# STM32H743 register map
File version: 2.4
CPU: CM7 r0p1, little endian, MPU, FPU, 4 interrupt priority bits
Registers are 32-bit, read-write, reset 0x0 unless marked. A register's access mark holds for its fields unless they carry their own. Offsets are from the block's base; [hi:lo] are bit positions; {n}, {i} and the like mark numbered series.

## LPUART1
Base 0x58000C00
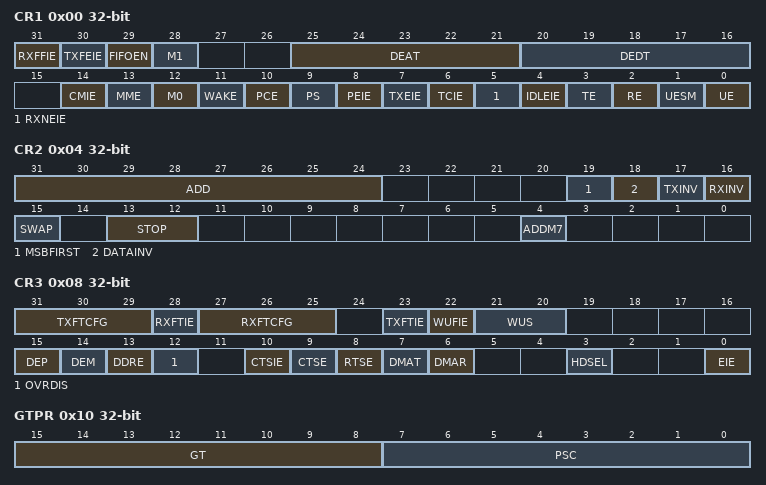
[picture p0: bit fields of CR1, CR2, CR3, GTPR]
0x00 CR1 — Control register 1
  [31] RXFFIE — RXFIFO Full interrupt enable
  [30] TXFEIE — TXFIFO empty interrupt enable
  [29] FIFOEN — FIFO mode enable
  [28] M1 — Word length
  [25:21] DEAT — Driver Enable assertion time
  [20:16] DEDT — Driver Enable deassertion time
  [14] CMIE — Character match interrupt enable
  [13] MME — Mute mode enable
  [12] M0 — Word length
  [11] WAKE — Receiver wakeup method
  [10] PCE — Parity control enable
  [9] PS — Parity selection
  [8] PEIE — PE interrupt enable
  [7] TXEIE — interrupt enable
  [6] TCIE — Transmission complete interrupt enable
  [5] RXNEIE — RXNE interrupt enable
  [4] IDLEIE — IDLE interrupt enable
  [3] TE — Transmitter enable
  [2] RE — Receiver enable
  [1] UESM — USART enable in Stop mode
  [0] UE — USART enable
0x04 CR2 — Control register 2
  [31:24] ADD — Address of the USART node
  [19] MSBFIRST — Most significant bit first
  [18] DATAINV — Binary data inversion
  [17] TXINV — TX pin active level inversion
  [16] RXINV — RX pin active level inversion
  [15] SWAP — Swap TX/RX pins
  [13:12] STOP — STOP bits
  [4] ADDM7 — 7-bit Address Detection/4-bit Address Detection
0x08 CR3 — Control register 3
  [31:29] TXFTCFG — TXFIFO threshold configuration
  [28] RXFTIE — RXFIFO threshold interrupt enable
  [27:25] RXFTCFG — Receive FIFO threshold configuration
  [23] TXFTIE — TXFIFO threshold interrupt enable
  [22] WUFIE — Wakeup from Stop mode interrupt enable
  [21:20] WUS — Wakeup from Stop mode interrupt flag selection
  [15] DEP — Driver enable polarity selection
  [14] DEM — Driver enable mode
  [13] DDRE — DMA Disable on Reception Error
  [12] OVRDIS — Overrun Disable
  [10] CTSIE — CTS interrupt enable
  [9] CTSE — CTS enable
  [8] RTSE — RTS enable
  [7] DMAT — DMA enable transmitter
  [6] DMAR — DMA enable receiver
  [3] HDSEL — Half-duplex selection
  [0] EIE — Error interrupt enable
0x0C BRR — Baud rate register
  [19:0] BRR
0x10 GTPR — Guard time and prescaler register
  [15:8] GT — Guard time value
  [7:0] PSC — Prescaler value
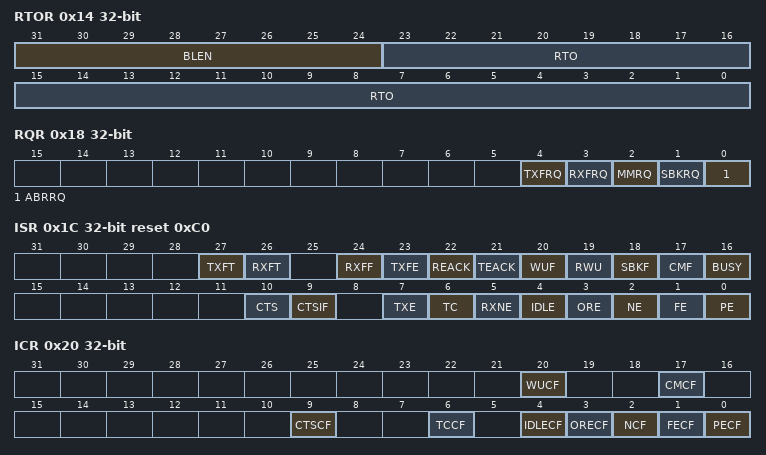
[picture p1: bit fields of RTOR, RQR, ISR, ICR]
0x14 RTOR — Receiver timeout register
  [31:24] BLEN — Block Length
  [23:0] RTO — Receiver timeout value
0x18 RQR wo — Request register
  [4] TXFRQ — Transmit data flush request
  [3] RXFRQ — Receive data flush request
  [2] MMRQ — Mute mode request
  [1] SBKRQ — Send break request
  [0] ABRRQ — Auto baud rate request
0x1C ISR ro reset 0xC0 — Interrupt & status register
  [27] TXFT — TXFIFO threshold flag
  [26] RXFT — RXFIFO threshold flag
  [24] RXFF — RXFIFO Full
  [23] TXFE — TXFIFO Empty
  [22] REACK
  [21] TEACK
  [20] WUF
  [19] RWU
  [18] SBKF
  [17] CMF
  [16] BUSY
  [10] CTS
  [9] CTSIF
  [7] TXE
  [6] TC
  [5] RXNE
  [4] IDLE
  [3] ORE
  [2] NE
  [1] FE
  [0] PE
0x20 ICR wo — Interrupt flag clear register
  [20] WUCF — Wakeup from Stop mode clear flag
  [17] CMCF — Character match clear flag
  [9] CTSCF — CTS clear flag
  [6] TCCF — Transmission complete clear flag
  [4] IDLECF — Idle line detected clear flag
  [3] ORECF — Overrun error clear flag
  [2] NCF — Noise detected clear flag
  [1] FECF — Framing error clear flag
  [0] PECF — Parity error clear flag
0x24 RDR ro — Receive data register
  [8:0] RDR — Receive data value
0x28 TDR — Transmit data register
  [8:0] TDR — Transmit data value
0x2C PRESC — Prescaler register
  [3:0] PRESCALER — Clock prescaler

## RAMECC1 — ECC controller is associated to each RAM area
Base 0x52009000
Same registers: RAMECC2 0x48023000
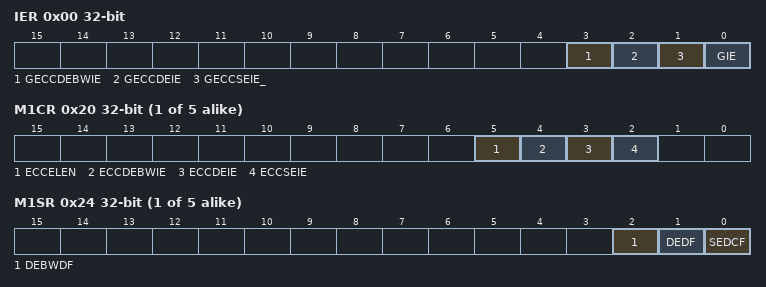
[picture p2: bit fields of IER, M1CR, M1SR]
0x00 IER — RAMECC interrupt enable register
  [3] GECCDEBWIE — Global ECC double error on byte write (BW) interrupt enable
  [2] GECCDEIE — Global ECC double error interrupt enable
  [1] GECCSEIE_ — Global ECC single error interrupt enable
  [0] GIE — Global interrupt enable
{0x0+0x20*i} M{i}CR (i=1..5) — RAMECC monitor x configuration register
  [5] ECCELEN — ECC error latching enable
  [4] ECCDEBWIE — ECC double error on byte write (BW) interrupt enable
  [3] ECCDEIE — ECC double error interrupt enable
  [2] ECCSEIE — ECC single error interrupt enable
{0x4+0x20*i} M{i}SR (i=1..5) — RAMECC monitor x status register
  [2] DEBWDF — ECC double error on byte write (BW) detected flag
  [1] DEDF — ECC double error detected flag
  [0] SEDCF — ECC single error detected and corrected flag
{0x8+0x20*i} M{i}FAR ro (i=1..4) — RAMECC monitor x failing address register
  [31:0] FADD — ECC error failing address
{0xC+0x20*i} M{i}FDRL ro (i=1..5) — RAMECC monitor x failing data low register
  [31:0] FDATAL — Failing data low
0x30 M1FDRH ro — RAMECC monitor x failing data high register
  [31:0] FDATAH — Failing data high (64-bit memory)
0x34 M1FECR — RAMECC monitor x failing ECC error code register
  [31:0] FEC — Failing error code
0x50 M2FDRH — RAMECC monitor x failing data high register
  [31:0] FDATAH — Failing data high (64-bit memory)
0x58 M2FECR — RAMECC monitor x failing ECC error code register
  [31:0] FEC — Failing error code
0x70 M3FDRH ro — RAMECC monitor x failing data high register
  [31:0] FDATAH — Failing data high (64-bit memory)
0x7C M3FECR ro — RAMECC monitor x failing ECC error code register
  [31:0] FEC — Failing error code
0x90 M4FDRH ro — RAMECC monitor x failing data high register
  [31:0] FDATAH — Failing data high (64-bit memory)
0x90 M4FECR ro (alternate view of M4FDRH) — RAMECC monitor x failing ECC error code register
  [31:0] FEC — Failing error code
0xA8 M5FAR — RAMECC monitor x failing address register
  [31:0] FADD — ECC error failing address
0xB0 M5FDRH ro — RAMECC monitor x failing data high register
  [31:0] FEC — Failing error code
0xB4 M5FECR ro — RAMECC monitor x failing ECC error code register
  [31:0] FEC — Failing error code

## RAMECC3 — ECC controller is associated to each RAM area
Base 0x58027000
Registers as RAMECC1, without M{n}CR (n=3..5), M{n}SR (n=3..5), M{n}FAR (n=3..5), M{n}FDRL (n=3..5), M{n}FDRH (n=3..5), M{n}FECR (n=3..5).

## Notices in the file
Copyright (c) 2025 STMicroelectronics.
SPDX-License-Identifier: Apache-2.0
Licensed under the Apache License, Version 2.0 (the "License");
you may not use this file except in compliance with the License.
You may obtain a copy of the License at
http://www.apache.org/licenses/LICENSE-2.0
Unless required by applicable law or agreed to in writing, software
distributed under the License is distributed on an "AS IS" BASIS,
WITHOUT WARRANTIES OR CONDITIONS OF ANY KIND, either express or implied.
See the License for the specific language governing permissions and
limitations under the License.
